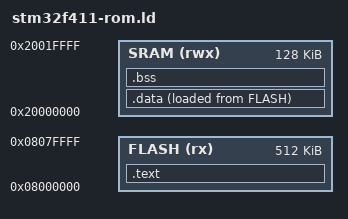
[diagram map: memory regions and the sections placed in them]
ENTRY(reset_handler)

MEMORY
{
  FLASH (rx)  : ORIGIN = 0x08000000, LENGTH = 512K
  SRAM  (rwx) : ORIGIN = 0x20000000, LENGTH = 128K
}

SECTIONS
{
  .text :
  {
    KEEP(*(.isr_vectors))
    *(.text*)
    *(.rodata*)
    . = ALIGN(4);
  } > FLASH

  .data :
  {
    _sdata = .;
    *(.data*)
    . = ALIGN(4);
    _edata = .;
  } > SRAM AT> FLASH

  _la_data = LOADADDR(.data);

  .bss :
  {
    _sbss = .;
    *(.bss*)
    *(COMMON)
    . = ALIGN(4);
    _ebss = .;
  } > SRAM
}
